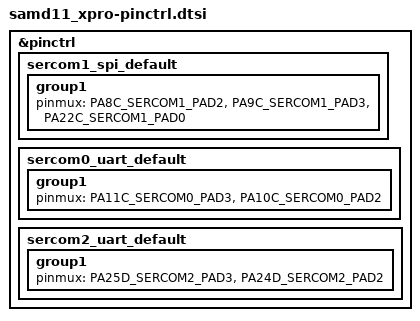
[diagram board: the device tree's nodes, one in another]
/*
 * Copyright (c) 2022, Gerson Fernando Budke <nandojve@gmail.com>
 * SPDX-License-Identifier: Apache-2.0
 */

 #include <dt-bindings/pinctrl/samd11d-pinctrl.h>

 &pinctrl { 
 
	 sercom1_spi_default: sercom1_spi_default {
		group1 {
			pinmux = <PA8C_SERCOM1_PAD2>,   //PA8 DATA IN
				     <PA9C_SERCOM1_PAD3>,   //PA9 SCK
					 <PA22C_SERCOM1_PAD0>;  //PA22 DATA OUT
		};
		status = "okay";
	 };
 
	 sercom0_uart_default: sercom0_uart_default {
		group1 {
			pinmux = <PA11C_SERCOM0_PAD3>,
			         <PA10C_SERCOM0_PAD2>;
			
		};
		status = "okay";
	 };

	 sercom2_uart_default: sercom2_uart_default {
		group1 {
			pinmux = <PA25D_SERCOM2_PAD3>,
                 <PA24D_SERCOM2_PAD2>;
		};
		 status = "okay";
	 };
 };
 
